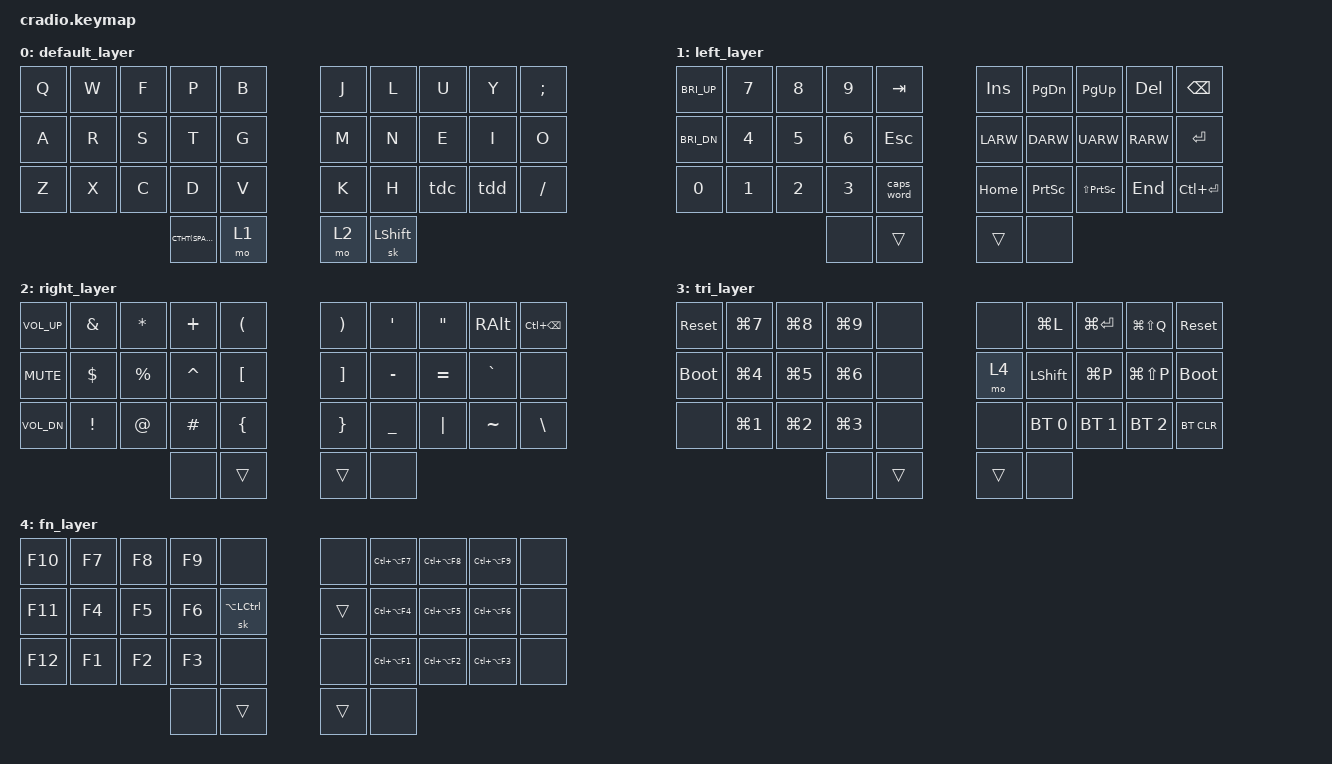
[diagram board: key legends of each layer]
// Copyright (c) 2022 The ZMK Contributors
// SPDX-License-Identifier: MIT

#include <behaviors.dtsi>
#include <dt-bindings/zmk/keys.h>
#include <dt-bindings/zmk/bt.h>

// Home row mods macro
#define CTHT(k1) &ht LCTRL k1 

/ {
    behaviors {
        ht: hold_tap {
            label = "hold_tap";
            compatible = "zmk,behavior-hold-tap";
            #binding-cells = <2>;
            flavor = "balanced";
            tapping-term-ms = <200>;
            quick-tap-ms = <150>;
            global-quick-tap;
            bindings = <&kp>, <&kp>;
        };
        tdd: tap_dance_0 {
            compatible = "zmk,behavior-tap-dance";
            #binding-cells = <0>;
            tapping-term-ms = <200>;
            bindings = <&kp DOT>, <&kp COLON>;
        };
        tdc: tap_dance_1 {
            compatible = "zmk,behavior-tap-dance";
            #binding-cells = <0>;
            tapping-term-ms = <200>;
            bindings = <&kp COMMA>, <&kp SEMI>;
        };
    };

    conditional_layers {
        compatible = "zmk,conditional-layers";
        tri_layer {
            if-layers = <1 2>;
            then-layer = <3>;
        };
    };

    keymap {
        compatible = "zmk,keymap";
        default_layer {
            bindings = <
        //╭──────────┬──────────┬──────────┬──────────┬──────────╮   ╭──────────┬──────────┬──────────┬──────────┬──────────╮
        //│  Q       │  W       │  E       │  R       │  T       │   │  Y       │  U       │  I       │  O       │  P       │
            &kp Q      &kp W      &kp F      &kp P      &kp B          &kp J      &kp L      &kp U      &kp Y      &kp SEMI
        //├──────────┼──────────┼──────────┼──────────┼──────────┤   ├──────────┼──────────┼──────────┼──────────┼──────────┤
        //│  A       │  S       │  D       │  F       │  G       │   │  H       │  J       │  K       │  L       │ ; :      │
            &kp A      &kp R      &kp S      &kp T      &kp G          &kp M      &kp N      &kp E      &kp I      &kp O
        //├──────────┼──────────┼──────────┼──────────┼──────────┤   ├──────────┼──────────┼──────────┼──────────┼──────────┤
        //│  Z       │  X       │  C       │  V       │  B       │   │  N       │  M       │ , <      │ . >      │ / ?      │
            &kp Z      &kp X      &kp C      &kp D      &kp V          &kp K      &kp H      &tdc       &tdd    &kp FSLH
        //╰──────────┴──────────┴──────────┼──────────┼──────────┤   ├──────────┼──────────┼──────────┴──────────┴──────────╯
                                             CTHT(SPACE) &mo 1          &mo 2      &sk LSHIFT
        //                                 ╰──────────┴──────────╯   ╰──────────┴──────────╯
            >;
        };

        left_layer {
            bindings = <
        //╭──────────┬──────────┬──────────┬──────────┬──────────╮   ╭──────────┬──────────┬──────────┬──────────┬──────────╮
        //│ BRIGHT+  │  7       │  8       │  9       │          │   │ INSERT   │ PAGE DN  │ PAGE UP  │ DEL      │          │
            &kp C_BRI_UP &kp N7   &kp N8     &kp N9     &kp TAB        &kp INS   &kp PG_DN  &kp PG_UP  &kp DEL    &kp BSPC
        //├──────────┼──────────┼──────────┼──────────┼──────────┤   ├──────────┼──────────┼──────────┼──────────┼──────────┤
        //│ BRIGHT-  │  4       │  5       │  6       │          │   │ LEFT     │ DOWN     │ UP       │ RIGHT    │          │
            &kp C_BRI_DN &kp N4   &kp N5     &kp N6     &kp ESC        &kp LARW   &kp DARW   &kp UARW   &kp RARW   &kp ENTER
        //├──────────┼──────────┼──────────┼──────────┼──────────┤   ├──────────┼──────────┼──────────┼──────────┼──────────┤
        //│ 0        │  1       │  2       │  3       │  CAPS    │   │ HOME     │          │          │ END      │          │
            &kp N0     &kp N1     &kp N2     &kp N3     &caps_word     &kp HOME   &kp PSCRN  &kp LS(PSCRN) &kp END    &kp LC(ENTER)
        //╰──────────┴──────────┴──────────┼──────────┼──────────┤   ├──────────┼──────────┼──────────┴──────────┴──────────╯
                                             &none     &trans        &trans     &none
        //                                 ╰──────────┴──────────╯   ╰──────────┴──────────╯
            >;
        };

        right_layer {
            bindings = <
        //╭──────────┬──────────┬──────────┬──────────┬──────────╮   ╭──────────┬──────────┬──────────┬──────────┬──────────╮
        //│          │  &       │  *       │  +       │  (       │   │  )       │  '       │  "       │  RALT    │          │
           &kp C_VOL_UP &kp AMPS  &kp ASTRK  &kp PLUS   &kp LPAR       &kp RPAR   &kp APOS  &kp DQT     &kp RALT   &kp LC(BSPC)
        //├──────────┼──────────┼──────────┼──────────┼──────────┤   ├──────────┼──────────┼──────────┼──────────┼──────────┤
        //│  !       │  $       │  %       │  ^       │  [       │   │  ]       │  -       │  =       │  `       │          │
           &kp C_MUTE  &kp DLLR   &kp PRCNT  &kp CARET  &kp LBKT       &kp RBKT   &kp MINUS  &kp EQUAL  &kp GRAVE  &none
        //├──────────┼──────────┼──────────┼──────────┼──────────┤   ├──────────┼──────────┼──────────┼──────────┼──────────┤
        //│          │  !       │  @       │  #       │  {       │   │  }       │  _       │  |       │  ~       │  \       │
           &kp C_VOL_DN &kp EXCL  &kp AT     &kp HASH   &kp LBRC       &kp RBRC   &kp UNDER  &kp PIPE   &kp TILDE  &kp BSLH
        //╰──────────┴──────────┴──────────┼──────────┼──────────┤   ├──────────┼──────────┼──────────┴──────────┴──────────╯
                                             &none     &trans         &trans     &none
        //                                 ╰──────────┴──────────╯   ╰──────────┴──────────╯
            >;
        };

        tri_layer {
            bindings = <
        //╭──────────┬──────────┬──────────┬──────────┬──────────╮   ╭──────────┬──────────┬──────────┬──────────┬──────────╮
        //│ RESET    │  WIN 7   │  WIN 8   │  WIN 9   │          │   │PROFILE 0 │          │          │          │  RESET   │
           &sys_reset  &kp LG(N7) &kp LG(N8) &kp LG(N9) &none           &none   &kp LG(L) &kp LG(ENTER)  &kp LG(LS(Q)) &sys_reset
        //├──────────┼──────────┼──────────┼──────────┼──────────┤   ├──────────┼──────────┼──────────┼──────────┼──────────┤
        //│BOOTLOADER│  WIN 4   │  WIN 5   │  WIN 6   │          │   │PROFILE 1 │  SHIFT   │          │          │BOOTLOADER│
          &bootloader  &kp LG(N4) &kp LG(N5) &kp LG(N6) &none           &mo 4   &kp LSHFT  &kp LG(P)  &kp LG(LS(P)) &bootloader
        //├──────────┼──────────┼──────────┼──────────┼──────────┤   ├──────────┼──────────┼──────────┼──────────┼──────────┤
        //│          │  WIN 1   │  WIN 2   │  WIN 3   │          │   │PROFILE 2 │ CLEAR BT │          │          │          │
            &none     &kp LG(N1) &kp LG(N2) &kp LG(N3) &none            &none   &bt BT_SEL 0 &bt BT_SEL 1 &bt BT_SEL 2 &bt BT_CLR
        //╰──────────┴──────────┴──────────┼──────────┼──────────┤   ├──────────┼──────────┼──────────┴──────────┴──────────╯
                                             &none     &trans         &trans     &none
        //                                 ╰──────────┴──────────╯   ╰──────────┴──────────╯
            >;
        };

        fn_layer {
            bindings = <
        // //╭──────────┬──────────┬──────────┬──────────┬──────────╮   ╭──────────┬──────────┬──────────┬──────────┬──────────╮
        // //│ RESET    │  WIN 7   │  WIN 8   │  WIN 9   │          │   │PROFILE 0 │          │          │          │  RESET   │
        //    &kp F10      &kp F7  &kp F8      &kp F9      &none           &none   &kp LC(LA(F7)) &kp LC(LA(F8)) &kp LC(LA(F9)) &none
        // //├──────────┼──────────┼──────────┼──────────┼──────────┤   ├──────────┼──────────┼──────────┼──────────┼──────────┤
        // //│BOOTLOADER│  WIN 4   │  WIN 5   │  WIN 6   │          │   │PROFILE 1 │  SHIFT   │          │          │BOOTLOADER│
        //   &kp F11       &kp F4 &kp F5       &kp F6      &sk(LC(LALT))   &trans  &kp LC(LA(F4)) &kp LC(LA(F5)) &kp LC(LA(F6)) &none
        // //├──────────┼──────────┼──────────┼──────────┼──────────┤   ├──────────┼──────────┼──────────┼──────────┼──────────┤
        // //│          │  WIN 1   │  WIN 2   │  WIN 3   │          │   │PROFILE 2 │ CLEAR BT │          │          │          │
        //     &kp F12     &kp F1 &kp F2       &kp F3      &none           &none   &bt LC(LA(F1)) &kp LC(LA(F2)) &kp LC(LA(F3)) &none
        // //╰──────────┴──────────┴──────────┼──────────┼──────────┤   ├──────────┼──────────┼──────────┴──────────┴──────────╯
        //                                      &none     &trans         &trans     &none
        // //                                 ╰──────────┴──────────╯   ╰──────────┴──────────╯

        //╭──────────┬──────────┬──────────┬──────────┬──────────╮   ╭──────────┬──────────┬──────────┬──────────┬──────────╮
        //│  Q       │  W       │  E       │  R       │  T       │   │  Y       │  U       │  I       │  O       │  P       │
            &kp F10    &kp F7     &kp F8     &kp F9     &none          &none      &kp LC(LA(F7)) &kp LC(LA(F8)) &kp LC(LA(F9))     &none
        //├──────────┼──────────┼──────────┼──────────┼──────────┤   ├──────────┼──────────┼──────────┼──────────┼──────────┤
        //│  A       │  S       │  D       │  F       │  G       │   │  H       │  J       │  K       │  L       │ ; :      │
            &kp F11    &kp F4     &kp F5     &kp F6     &sk LA(LCTRL)          &trans     &kp LC(LA(F4)) &kp LC(LA(F5)) &kp LC(LA(F6))     &none
        //├──────────┼──────────┼──────────┼──────────┼──────────┤   ├──────────┼──────────┼──────────┼──────────┼──────────┤
        //│  Z       │  X       │  C       │  V       │  B       │   │  N       │  M       │ , <      │ . >      │ / ?      │
            &kp F12    &kp F1     &kp F2     &kp F3     &none          &none      &kp LC(LA(F1)) &kp LC(LA(F2)) &kp LC(LA(F3))    &none
        //╰──────────┴──────────┴──────────┼──────────┼──────────┤   ├──────────┼──────────┼──────────┴──────────┴──────────╯
                                             &none      &trans          &trans    &none
        //                                 ╰──────────┴──────────╯   ╰──────────┴──────────╯
            >;
        };
    };
};
